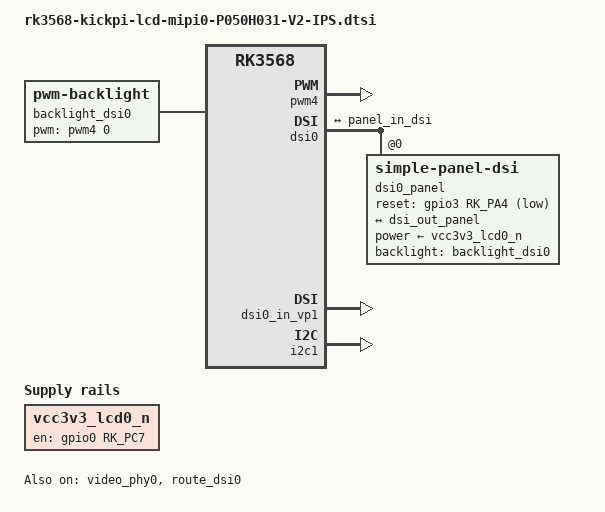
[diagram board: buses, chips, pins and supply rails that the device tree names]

/ {

	backlight_dsi0: backlight-dsi0 {
		compatible = "pwm-backlight";
		pwms = <&pwm4 0 25000 0>;
		brightness-levels = <
			  0  20  20  21  21  22  22  23
			 23  24  24  25  25  26  26  27
			 27  28  28  29  29  30  30  31
			 31  32  32  33  33  34  34  35
			 35  36  36  37  37  38  38  39
			 40  41  42  43  44  45  46  47
			 48  49  50  51  52  53  54  55
			 56  57  58  59  60  61  62  63
			 64  65  66  67  68  69  70  71
			 72  73  74  75  76  77  78  79
			 80  81  82  83  84  85  86  87
			 88  89  90  91  92  93  94  95
			 96  97  98  99 100 101 102 103
			104 105 106 107 108 109 110 111
			112 113 114 115 116 117 118 119
			120 121 122 123 124 125 126 127
			128 129 130 131 132 133 134 135
			136 137 138 139 140 141 142 143
			144 145 146 147 148 149 150 151
			152 153 154 155 156 157 158 159
			160 161 162 163 164 165 166 167
			168 169 170 171 172 173 174 175
			176 177 178 179 180 181 182 183
			184 185 186 187 188 189 190 191
			192 193 194 195 196 197 198 199
			200 201 202 203 204 205 206 207
			208 209 210 211 212 213 214 215
			216 217 218 219 220 221 222 223
			224 225 226 227 228 229 230 231
			232 233 234 235 236 237 238 239
			240 241 242 243 244 245 246 247
			248 249 250 251 252 253 254 255
		>;
		default-brightness-level = <200>;
	};

	vcc3v3_lcd0_n: vcc3v3-lcd0-n {
		compatible = "regulator-fixed";
		regulator-name = "vcc3v3_lcd0_n";
		regulator-boot-on;
		gpio = <&gpio0 RK_PC7 GPIO_ACTIVE_HIGH>;
		enable-active-high;
		regulator-state-mem {
			regulator-off-in-suspend;
		};
	};
};

&pwm4 {
	status = "okay";
};

/*
 * video_phy0 needs to be enabled
 * when dsi0 is enabled
 */
&dsi0 {
	status = "okay";
	//rockchip,lane-rate = <1000>;
	dsi0_panel: panel@0 {
		status = "okay";
		compatible = "simple-panel-dsi";
		reg = <0>;

		backlight = <&backlight_dsi0>;
		power-supply = <&vcc3v3_lcd0_n>;

		reset-gpios = <&gpio3 RK_PA4 GPIO_ACTIVE_LOW>;

		reset-delay-ms = <120>;
		enable-delay-ms = <120>;
		prepare-delay-ms = <120>;
		init-delay-ms = <120>;
		unprepare-delay-ms = <60>;
		disable-delay-ms = <60>;

		dsi,flags = <(MIPI_DSI_MODE_VIDEO | MIPI_DSI_MODE_VIDEO_BURST |
			MIPI_DSI_MODE_LPM | MIPI_DSI_MODE_EOT_PACKET)>;
		dsi,format = <MIPI_DSI_FMT_RGB888>;
		dsi,lanes  = <4>;
		panel-init-sequence = [
			39 00 04 B9 F1 12 83
			39 00 1C BA 33 81 05 F9 0E 0E 20 00 00 00 00 00 00 00 44 25 00 91 0A 00 00 02 4F D1 00 00 37
			39 00 03 B8 25 22
			39 00 04 BF 02 10 00
			39 00 0B B3 07 0B 1E 1E 03 FF 00 00 00 00
			39 00 0A C0 73 73 50 50 00 00 08 70 00
			39 00 02 BC 46
			39 00 02 CC 0B
			39 00 02 B4 80
			39 00 04 B2 C8 02 30
			39 00 0F E3 07 07 0B 0B 03 0B 00 00 00 00 FF 80 C0 14
			39 00 07 C1 53 00 1E 1E 77 F1
			39 00 03 B5 09 09
			39 00 03 B6 B2 B2
			39 00 40 E9 C2 10 09 00 00 08 EA 12 30 00 27 85 08 EA 27 18 00 05 00 00 00 00 00 05 00 00 00 00 F8 BA 46 02 08 28 88 88 88 88 88 F8 BA 57 13 18 38 88 88 88 88 88 00 00 00 03 00 00 00 00 00 00 00 00 00
			39 00 3E EA 07 12 01 01 02 3C 00 00 00 00 00 00 8F BA 31 75 38 18 88 88 88 88 88 8F BA 20 64 28 08 88 88 88 88 88 23 10 00 00 04 00 00 00 00 00 00 00 00 00 00 00 00 00 00 00 00 00 00 00 00 00 00
			39 00 23 E0 00 05 09 15 0F 3F 2F 2D 05 0A 0C 11 13 10 10 1C 1F 00 03 03 17 11 3F 2F 2D 05 08 0E 0F 13 12 16 18 1D
			05 FA 01 11
			05 32 01 29
		];

		panel-exit-sequence = [
			05 00 01 28
			05 00 01 10
		];

		disp_timings0: display-timings {
			native-mode = <&dsi0_timing0>;
			dsi0_timing0: timing0 {
				clock-frequency = <62000000>;
				hactive = <720>;
				vactive = <1280>;
				hfront-porch = <26>;
				hsync-len = <4>;
				hback-porch = <34>;
				vfront-porch = <18>;
				vsync-len = <2>;
				vback-porch = <16>;
				hsync-active = <0>;
				vsync-active = <0>;
				de-active = <0>;
				pixelclk-active = <0>;
			};
		};

		ports {
			#address-cells = <1>;
			#size-cells = <0>;

			port@0 {
				reg = <0>;
				panel_in_dsi: endpoint {
					remote-endpoint = <&dsi_out_panel>;
				};
			};
		};
	};

	ports {
		#address-cells = <1>;
		#size-cells = <0>;

		port@1 {
			reg = <1>;
			dsi_out_panel: endpoint {
				remote-endpoint = <&panel_in_dsi>;
			};
		};
	};
};

&dsi0_in_vp0 {
	status = "disabled";
};

&dsi0_in_vp1 {
	status = "okay";
};

&video_phy0 {
	status = "okay";
};

&route_dsi0 {
	status = "okay";
	connect = <&vp1_out_dsi0>;
};

&i2c1 {
	status = "okay";

	myft5x06: my-ft5x06@38 {
        compatible = "focaltech,fts";
        reg = <0x38>; 
		status = "disabled";
 
        focaltech,reset-gpio = <&gpio0 RK_PB6 GPIO_ACTIVE_LOW>;
        focaltech,irq-gpio = <&gpio3 RK_PA3 IRQ_TYPE_LEVEL_LOW>;
 
        pinctrl-names = "default";
        pinctrl-0 = <&touch1_gpio>;

		focaltech,display-coords = <0 0 720 1280>;
		focaltech,max-touch-number = <10>;
 
    };

	gt9xx:gt9xx@5d {
		compatible = "goodix,gt9xx";
		status = "disabled";
		reg = <0x5d>;

		gtp_resolution_x = <720>;
		gtp_resolution_y = <1280>;
		gtp_int_tarigger = <1>;
		//gtp_change_x2y = <1>;
		//gtp_overturn_x = <1>;
		//gtp_overturn_y = <0>;
		gtp_send_cfg = <0>;
		gtp_touch_wakeup = <1>;
		goodix_rst_gpio = <&gpio0 RK_PB6 GPIO_ACTIVE_HIGH>;
		goodix_irq_gpio = <&gpio3 RK_PA3 IRQ_TYPE_LEVEL_LOW>;
		pinctrl-names = "default";
		pinctrl-0 = <&touch1_gpio>;

		goodix,cfg-group0 = [
			70 20 03 00 05 05 35 00 01 0A
			28 0F 5A 3C 03 05 00 00 00 00
			00 00 06 18 1A 1E 14 8C 2E 0E
			B0 B2 B2 04 00 00 00 98 02 1C
			00 01 00 00 00 03 64 32 00 00
			00 A0 F5 94 D5 02 07 00 00 04
			83 A7 00 7E B5 00 78 C6 00 73
			D7 00 6F EA 00 6F 00 00 00 00
			00 00 00 00 00 00 00 00 00 00
			00 00 00 00 00 00 00 00 00 00
			00 00 00 00 00 00 00 00 00 00
			00 00 1C 1A 18 16 14 12 10 0E
			0C 0A 08 06 04 02 FF FF FF FF
			FF FF FF FF FF FF FF FF FF FF
			FF FF 00 02 04 06 08 0A 0C 0F
			10 12 13 14 16 2A 29 28 26 24
			22 21 20 1F 1E 1D 1C 18 FF FF
			FF FF FF FF FF FF FF FF FF FF
			FF FF FF FF FC 01
		];
		
	};
};

&pinctrl {
	touch1 {
		touch1_gpio: touch-gpio {
			rockchip,pins =
				<3 RK_PA3 RK_FUNC_GPIO &pcfg_pull_up>,
				<0 RK_PB6 RK_FUNC_GPIO &pcfg_pull_none>;
		};
	};
};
